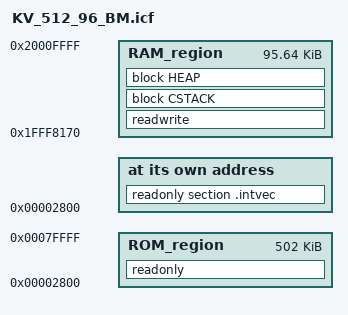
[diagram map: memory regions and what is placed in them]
/* KV_512_96_BM.icf - for target in Flash, together with boot loader     */
/* 512k Flash / 96k RAM                                                  */
/*                     Vectors are in flash                              */

/*********** adjust to suit boot loader *****************************/

define symbol __ICFEDIT_intvec_start__ = 0x00002800;
                                                        
/********************************************************************/

/*-Memory Regions-*/
define symbol __ICFEDIT_region_ROM_start__ = __ICFEDIT_intvec_start__;
define symbol __ICFEDIT_region_ROM_end__   = 0x0007ffff;
define symbol __ICFEDIT_region_RAM_start__ = 0x1fff8170;
define symbol __ICFEDIT_region_RAM_end__   = 0x2000ffff;
/*-Sizes-*/
define symbol __ICFEDIT_size_cstack__ = 0x0;
define symbol __ICFEDIT_size_heap__   = 0x0;


define memory mem with size = 4G;
define region ROM_region   = mem:[from __ICFEDIT_region_ROM_start__   to __ICFEDIT_region_ROM_end__];
define region RAM_region   = mem:[from __ICFEDIT_region_RAM_start__   to __ICFEDIT_region_RAM_end__];

define block CSTACK    with alignment = 8, size = __ICFEDIT_size_cstack__   { };
define block HEAP      with alignment = 8, size = __ICFEDIT_size_heap__     { };


initialize by copy { readwrite };
do not initialize  { section .noinit };

place at address mem:__ICFEDIT_intvec_start__ { readonly section .intvec };

place in ROM_region   { readonly };
place in RAM_region   { readwrite,
                        block CSTACK, block HEAP };
